VERSION ""

NS_ :

BS_:

BU_: BMS FRONT_SENSOR IMU INV LOGGER REAR_SENSOR VCU VCU_HP

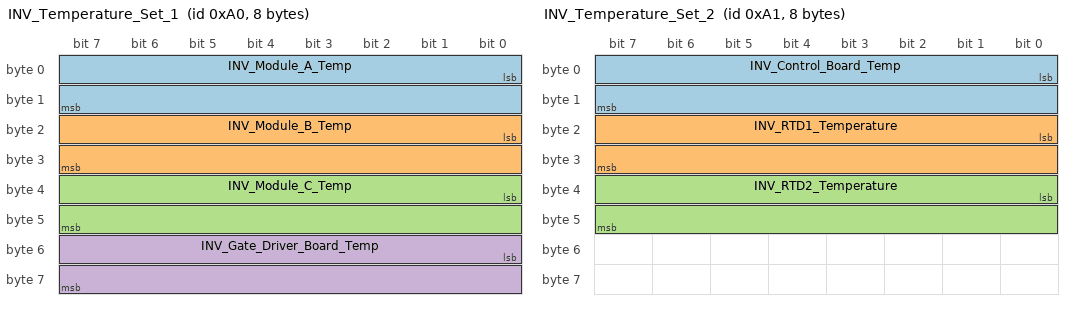
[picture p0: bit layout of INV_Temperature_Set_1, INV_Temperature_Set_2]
BO_ 160 INV_Temperature_Set_1: 8 INV
	SG_ INV_Module_A_Temp : 0|16@1- (0.1,0) [-3276.8|3276.7] "temperature:C" LOGGER
	SG_ INV_Module_B_Temp : 16|16@1- (0.1,0) [-3276.8|3276.7] "temperature:C" LOGGER
	SG_ INV_Module_C_Temp : 32|16@1- (0.1,0) [-3276.8|3276.7] "temperature:C" LOGGER
	SG_ INV_Gate_Driver_Board_Temp : 48|16@1- (0.1,0) [-3276.8|3276.7] "temperature:C" LOGGER

BO_ 161 INV_Temperature_Set_2: 8 INV
	SG_ INV_Control_Board_Temp : 0|16@1- (0.1,0) [-3276.8|3276.7] "temperature:C" LOGGER
	SG_ INV_RTD1_Temperature : 16|16@1- (0.1,0) [-3276.8|3276.7] "temperature:C" LOGGER
	SG_ INV_RTD2_Temperature : 32|16@1- (0.1,0) [-3276.8|3276.7] "temperature:C" LOGGER

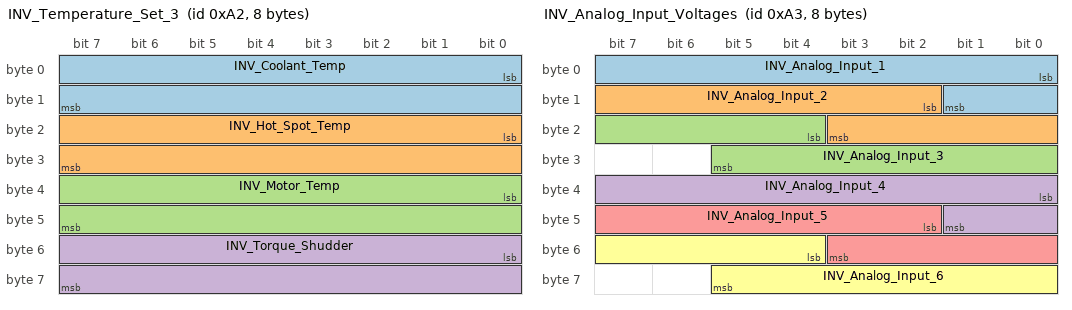
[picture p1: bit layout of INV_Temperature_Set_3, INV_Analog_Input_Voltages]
BO_ 162 INV_Temperature_Set_3: 8 INV
	SG_ INV_Coolant_Temp : 0|16@1- (0.1,0) [-3276.8|3276.7] "temperature:C" LOGGER
	SG_ INV_Hot_Spot_Temp : 16|16@1- (0.1,0) [-3276.8|3276.7] "temperature:C" LOGGER
	SG_ INV_Motor_Temp : 32|16@1- (0.1,0) [-3276.8|3276.7] "temperature:C" LOGGER
	SG_ INV_Torque_Shudder : 48|16@1- (0.1,0) [-3276.8|3276.7] "torque:N.m" LOGGER

BO_ 163 INV_Analog_Input_Voltages: 8 INV
	SG_ INV_Analog_Input_1 : 0|10@1+ (0.01,0) [0|10.23] "voltage:V" Vector__XXX
	SG_ INV_Analog_Input_2 : 10|10@1+ (0.01,0) [0|10.23] "voltage:V" Vector__XXX
	SG_ INV_Analog_Input_3 : 20|10@1+ (0.01,0) [0|10.23] "voltage:V" Vector__XXX
	SG_ INV_Analog_Input_4 : 32|10@1+ (0.01,0) [0|10.23] "voltage:V" Vector__XXX
	SG_ INV_Analog_Input_5 : 42|10@1+ (0.01,0) [0|10.23] "voltage:V" Vector__XXX
	SG_ INV_Analog_Input_6 : 52|10@1+ (0.01,0) [0|10.23] "voltage:V" Vector__XXX

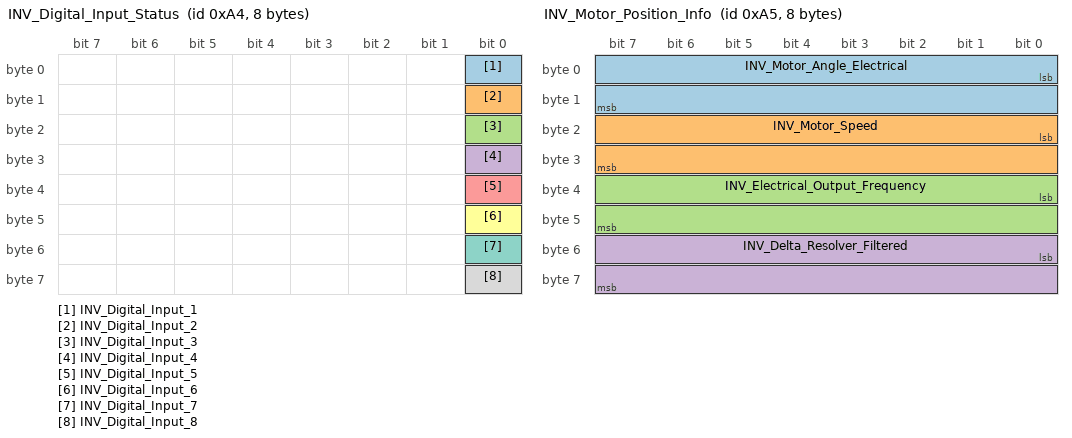
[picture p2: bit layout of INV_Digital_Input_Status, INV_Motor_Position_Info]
BO_ 164 INV_Digital_Input_Status: 8 INV
	SG_ INV_Digital_Input_1 : 0|1@1+ (1,0) [0|1] "" Vector__XXX
	SG_ INV_Digital_Input_2 : 8|1@1+ (1,0) [0|1] "" Vector__XXX
	SG_ INV_Digital_Input_3 : 16|1@1+ (1,0) [0|1] "" Vector__XXX
	SG_ INV_Digital_Input_4 : 24|1@1+ (1,0) [0|1] "" Vector__XXX
	SG_ INV_Digital_Input_5 : 32|1@1+ (1,0) [0|1] "" Vector__XXX
	SG_ INV_Digital_Input_6 : 40|1@1+ (1,0) [0|1] "" Vector__XXX
	SG_ INV_Digital_Input_7 : 48|1@1+ (1,0) [0|1] "" Vector__XXX
	SG_ INV_Digital_Input_8 : 56|1@1+ (1,0) [0|1] "" Vector__XXX

BO_ 165 INV_Motor_Position_Info: 8 INV
	SG_ INV_Motor_Angle_Electrical : 0|16@1+ (0.1,0) [0|6553.5] "angle:deg" LOGGER
	SG_ INV_Motor_Speed : 16|16@1- (1,0) [-32768|32767] "angular_speed:rpm" LOGGER
	SG_ INV_Electrical_Output_Frequency : 32|16@1- (0.1,0) [-3276.8|3276.7] "frequency:Hz" LOGGER
	SG_ INV_Delta_Resolver_Filtered : 48|16@1- (0.1,0) [-3276.8|3276.7] "angle:deg" LOGGER

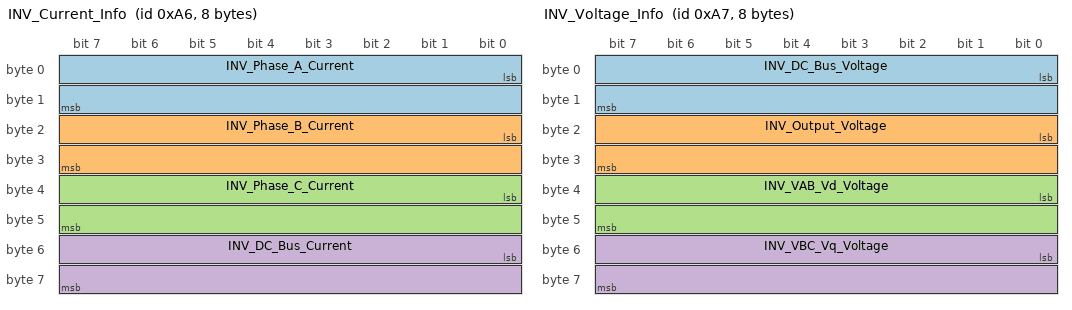
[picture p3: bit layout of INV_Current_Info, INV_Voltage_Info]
BO_ 166 INV_Current_Info: 8 INV
	SG_ INV_Phase_A_Current : 0|16@1- (0.1,0) [-3276.8|3276.7] "current:A" LOGGER
	SG_ INV_Phase_B_Current : 16|16@1- (0.1,0) [-3276.8|3276.7] "current:A" LOGGER
	SG_ INV_Phase_C_Current : 32|16@1- (0.1,0) [-3276.8|3276.7] "current:A" LOGGER
	SG_ INV_DC_Bus_Current : 48|16@1- (0.1,0) [-3276.8|3276.7] "current:A" LOGGER

BO_ 167 INV_Voltage_Info: 8 INV
	SG_ INV_DC_Bus_Voltage : 0|16@1- (0.1,0) [-3276.8|3276.7] "voltage:V" LOGGER
	SG_ INV_Output_Voltage : 16|16@1- (0.1,0) [-3276.8|3276.7] "voltage:V" LOGGER
	SG_ INV_VAB_Vd_Voltage : 32|16@1- (0.1,0) [-3276.8|3276.7] "voltage:V" LOGGER
	SG_ INV_VBC_Vq_Voltage : 48|16@1- (0.1,0) [-3276.8|3276.7] "voltage:V" LOGGER

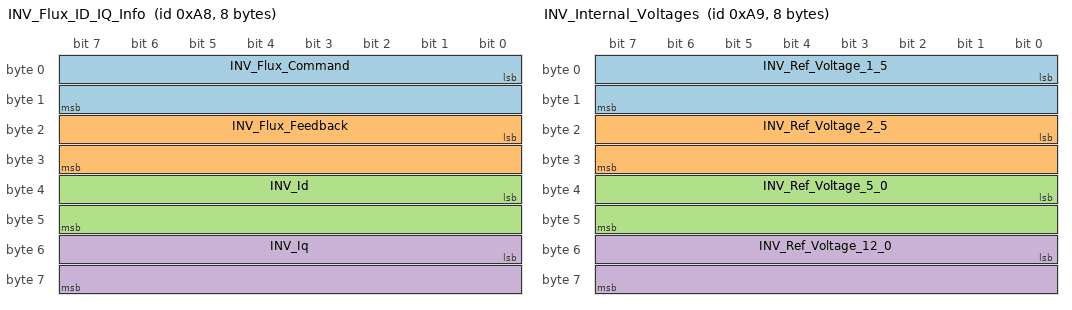
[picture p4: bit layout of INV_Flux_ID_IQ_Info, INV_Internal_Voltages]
BO_ 168 INV_Flux_ID_IQ_Info: 8 INV
	SG_ INV_Flux_Command : 0|16@1- (0.001,0) [-32.768|32.767] "flux:Wb" Vector__XXX
	SG_ INV_Flux_Feedback : 16|16@1- (0.001,0) [-32.768|32.767] "flux:Wb" Vector__XXX
	SG_ INV_Id : 32|16@1- (0.1,0) [-3276.8|3276.7] "current:A" Vector__XXX
	SG_ INV_Iq : 48|16@1- (0.1,0) [-3276.8|3276.7] "current:A" Vector__XXX

BO_ 169 INV_Internal_Voltages: 8 INV
	SG_ INV_Ref_Voltage_1_5 : 0|16@1- (0.01,0) [-327.68|327.67] "voltage:V" Vector__XXX
	SG_ INV_Ref_Voltage_2_5 : 16|16@1- (0.01,0) [-327.68|327.67] "voltage:V" Vector__XXX
	SG_ INV_Ref_Voltage_5_0 : 32|16@1- (0.01,0) [-327.68|327.67] "voltage:V" Vector__XXX
	SG_ INV_Ref_Voltage_12_0 : 48|16@1- (0.01,0) [-327.68|327.67] "voltage:V" Vector__XXX

BO_ 170 INV_Internal_States: 8 INV
	SG_ INV_VSM_State : 0|8@1+ (1,0) [0|15] "" LOGGER
	SG_ INV_PWM_Frequency : 8|8@1+ (1,0) [0|255] "" LOGGER
	SG_ INV_Inverter_State : 16|8@1+ (1,0) [0|255] "" LOGGER
	SG_ INV_Relay_1_Status : 24|1@1+ (1,0) [0|1] "" LOGGER
	SG_ INV_Relay_2_Status : 25|1@1+ (1,0) [0|1] "" LOGGER
	SG_ INV_Relay_3_Status : 26|1@1+ (1,0) [0|1] "" LOGGER
	SG_ INV_Relay_4_Status : 27|1@1+ (1,0) [0|1] "" LOGGER
	SG_ INV_Relay_5_Status : 28|1@1+ (1,0) [0|1] "" LOGGER
	SG_ INV_Relay_6_Status : 29|1@1+ (1,0) [0|1] "" LOGGER
	SG_ INV_Inverter_Run_Mode : 32|1@1+ (1,0) [0|1] "" LOGGER
	SG_ INV_Inverter_Discharge_State : 37|3@1+ (1,0) [0|7] "" LOGGER
	SG_ INV_Inverter_Command_Mode : 40|1@1+ (1,0) [0|1] "" LOGGER
	SG_ INV_Rolling_Counter : 44|4@1+ (1,0) [0|15] "" LOGGER
	SG_ INV_Inverter_Enable_State : 48|1@1+ (1,0) [0|1] "" LOGGER
	SG_ INV_Inverter_Enable_Lockout : 55|1@1+ (1,0) [0|1] "" LOGGER
	SG_ INV_Direction_Command : 56|1@1+ (1,0) [0|1] "" LOGGER
	SG_ INV_BMS_Active : 57|1@1+ (1,0) [0|1] "" LOGGER
	SG_ INV_BMS_Torque_Limiting : 58|1@1+ (1,0) [0|0] "" LOGGER
	SG_ INV_Limit_Max_Speed : 59|1@1+ (1,0) [0|1] "" LOGGER
	SG_ INV_Limit_Hot_Spot : 60|1@1+ (1,0) [0|1] "" LOGGER
	SG_ INV_Low_Speed_Limiting : 61|1@1+ (1,0) [0|1] "" LOGGER
	SG_ INV_Limit_Coolant_Derating : 62|1@1+ (1,0) [0|1] "" LOGGER

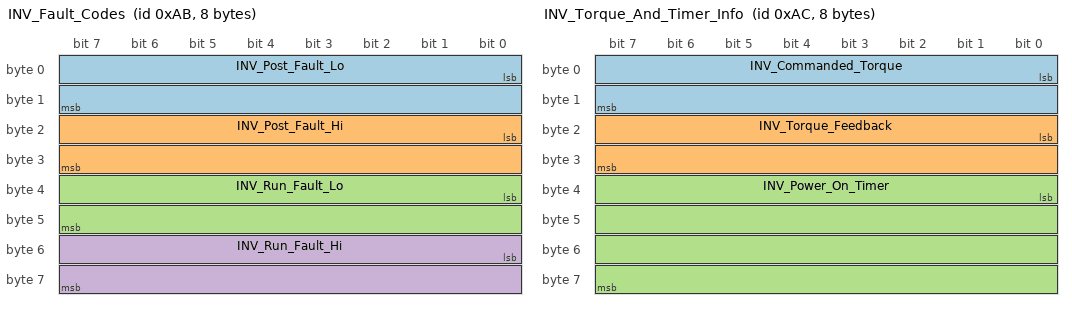
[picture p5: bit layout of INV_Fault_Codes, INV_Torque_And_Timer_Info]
BO_ 171 INV_Fault_Codes: 8 INV
	SG_ INV_Post_Fault_Lo : 0|16@1+ (1,0) [0|65535] "" LOGGER VCU
	SG_ INV_Post_Fault_Hi : 16|16@1+ (1,0) [0|65535] "" LOGGER VCU
	SG_ INV_Run_Fault_Lo : 32|16@1+ (1,0) [0|65535] "" LOGGER VCU
	SG_ INV_Run_Fault_Hi : 48|16@1+ (1,0) [0|65535] "" LOGGER VCU

BO_ 172 INV_Torque_And_Timer_Info: 8 INV
	SG_ INV_Commanded_Torque : 0|16@1- (0.1,0) [-3276.8|3276.7] "torque:N.m" Vector__XXX
	SG_ INV_Torque_Feedback : 16|16@1- (0.1,0) [-3276.8|3276.7] "torque:N.m" Vector__XXX
	SG_ INV_Power_On_Timer : 32|32@1+ (0.003,0) [0|12884800] "time:second" Vector__XXX

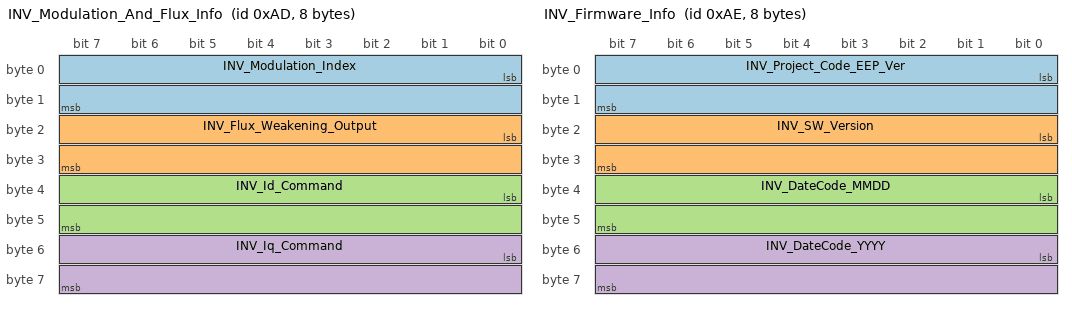
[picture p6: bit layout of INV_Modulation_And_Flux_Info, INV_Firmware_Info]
BO_ 173 INV_Modulation_And_Flux_Info: 8 INV
	SG_ INV_Modulation_Index : 0|16@1- (0.0001,0) [-3.2768|3.2767] "" Vector__XXX
	SG_ INV_Flux_Weakening_Output : 16|16@1- (0.1,0) [-3276.8|3276.7] "current:A" Vector__XXX
	SG_ INV_Id_Command : 32|16@1- (0.1,0) [-3276.8|3276.7] "current:A" Vector__XXX
	SG_ INV_Iq_Command : 48|16@1- (0.1,0) [-3276.8|3276.7] "current:A" Vector__XXX

BO_ 174 INV_Firmware_Info: 8 INV
	SG_ INV_Project_Code_EEP_Ver : 0|16@1+ (1,0) [0|65535] "" Vector__XXX
	SG_ INV_SW_Version : 16|16@1+ (1,0) [0|65535] "" Vector__XXX
	SG_ INV_DateCode_MMDD : 32|16@1+ (1,0) [0|65535] "" Vector__XXX
	SG_ INV_DateCode_YYYY : 48|16@1+ (1,0) [0|65535] "" Vector__XXX

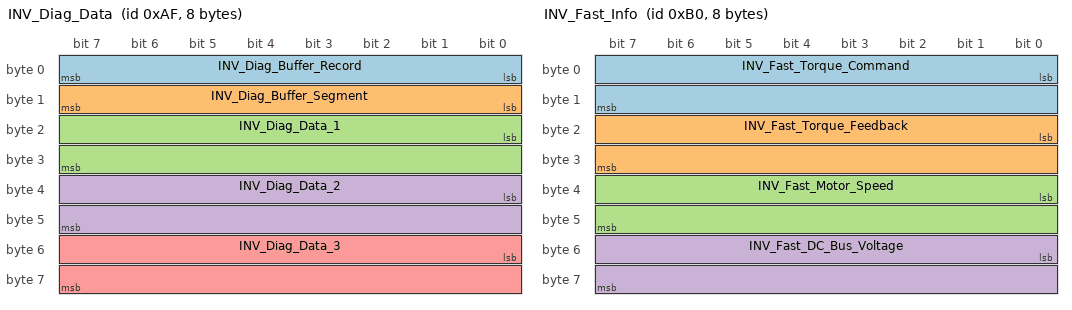
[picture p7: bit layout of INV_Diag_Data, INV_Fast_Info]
BO_ 175 INV_Diag_Data: 8 INV
	SG_ INV_Diag_Buffer_Record : 0|8@1+ (1,0) [0|255] "" Vector__XXX
	SG_ INV_Diag_Buffer_Segment : 8|8@1+ (1,0) [0|5] "" Vector__XXX
	SG_ INV_Diag_Data_1 : 16|16@1- (1,0) [-32768|32767] "" Vector__XXX
	SG_ INV_Diag_Data_2 : 32|16@1- (1,0) [-32768|32767] "" Vector__XXX
	SG_ INV_Diag_Data_3 : 48|16@1- (1,0) [-32768|32767] "" Vector__XXX

BO_ 176 INV_Fast_Info: 8 INV
	SG_ INV_Fast_Torque_Command : 0|16@1- (0.1,0) [-3276.8|32767.7] "torque:N.m" LOGGER, VCU_HP
	SG_ INV_Fast_Torque_Feedback : 16|16@1- (0.1,0) [-3276.8|3276.7] "torque:N.m" LOGGER, VCU_HP
	SG_ INV_Fast_Motor_Speed : 32|16@1- (1,0) [-32768|32767] "angular_speed:rpm" LOGGER, VCU_HP
	SG_ INV_Fast_DC_Bus_Voltage : 48|16@1- (0.1,0) [-3276.8|3276.7] "voltage:V" LOGGER, VCU_HP

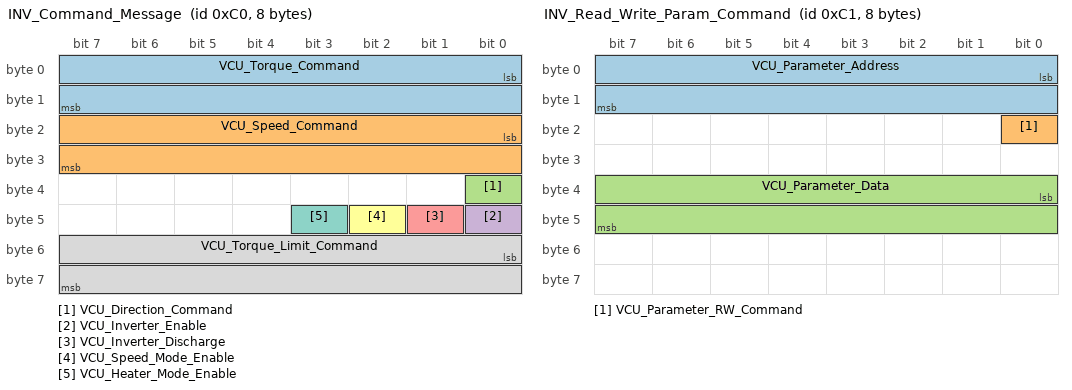
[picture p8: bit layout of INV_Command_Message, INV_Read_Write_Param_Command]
BO_ 192 INV_Command_Message: 8 VCU
	SG_ VCU_Torque_Command : 0|16@1- (0.1,0) [-3276.8|3276.7] "torque:N.m" INV, LOGGER
	SG_ VCU_Speed_Command : 16|16@1- (1,0) [-32768|32767] "angular_speed:rpm" INV, LOGGER
	SG_ VCU_Direction_Command : 32|1@1+ (1,0) [0|1] "" INV, LOGGER
	SG_ VCU_Inverter_Enable : 40|1@1+ (1,0) [0|1] "" INV, LOGGER
	SG_ VCU_Inverter_Discharge : 41|1@1+ (1,0) [0|1] "" INV, LOGGER
	SG_ VCU_Speed_Mode_Enable : 42|1@1+ (1,0) [0|1] "" INV, LOGGER
	SG_ VCU_Heater_Mode_Enable : 43|1@1+ (1,0) [0|0] "" INV, LOGGER
	SG_ VCU_Torque_Limit_Command : 48|16@1- (0.1,0) [-3276.8|3276.7] "torque:N.m" INV, LOGGER

BO_ 193 INV_Read_Write_Param_Command: 8 Vector__XXX
	SG_ VCU_Parameter_Address : 0|16@1+ (1,0) [0|65535] "" INV
	SG_ VCU_Parameter_RW_Command : 16|1@1+ (1,0) [0|1] "" INV
	SG_ VCU_Parameter_Data : 32|16@1- (1,0) [-32768|32767] "" INV

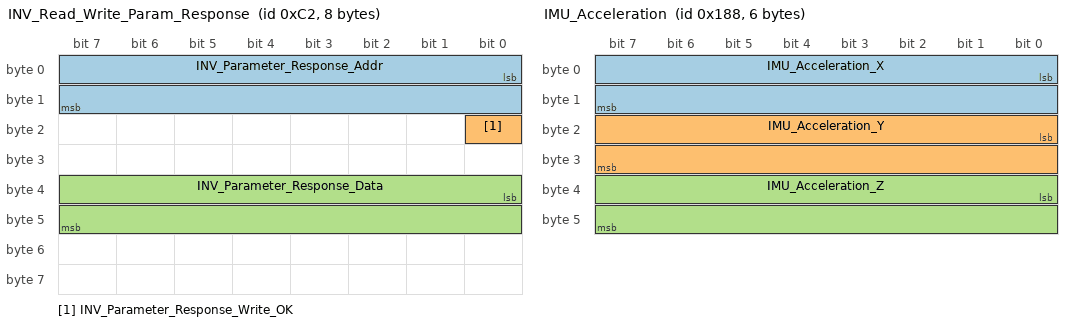
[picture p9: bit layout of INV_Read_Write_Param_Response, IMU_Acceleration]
BO_ 194 INV_Read_Write_Param_Response: 8 INV
	SG_ INV_Parameter_Response_Addr : 0|16@1+ (1,0) [0|65535] "" Vector__XXX
	SG_ INV_Parameter_Response_Write_OK : 16|1@1+ (1,0) [0|1] "" Vector__XXX
	SG_ INV_Parameter_Response_Data : 32|16@1- (1,0) [-32768|32767] "" Vector__XXX

BO_ 392 IMU_Acceleration: 6 IMU
	SG_ IMU_Acceleration_X : 0|16@1- (0.001,0) [-8|8] "acceleration:G" LOGGER
	SG_ IMU_Acceleration_Y : 16|16@1- (0.001,0) [-8|8] "acceleration:G" LOGGER
	SG_ IMU_Acceleration_Z : 32|16@1- (0.001,0) [-8|8] "acceleration:G" LOGGER

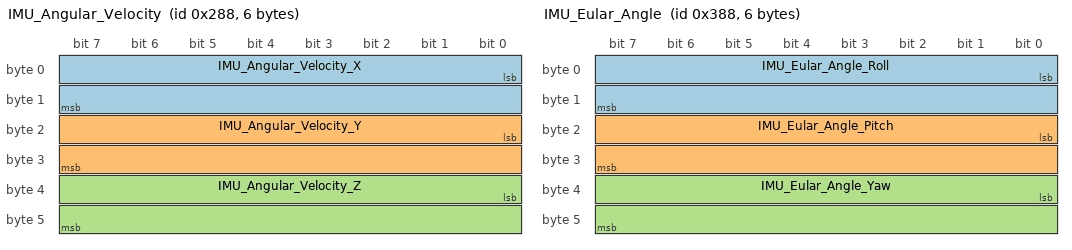
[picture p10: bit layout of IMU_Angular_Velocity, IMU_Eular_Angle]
BO_ 648 IMU_Angular_Velocity: 6 IMU
	SG_ IMU_Angular_Velocity_X : 0|16@1- (0.1,0) [-2000|2000] "angular_velocity:deg/s" LOGGER
	SG_ IMU_Angular_Velocity_Y : 16|16@1- (0.1,0) [-2000|2000] "angular_velocity:deg/s" LOGGER
	SG_ IMU_Angular_Velocity_Z : 32|16@1- (0.1,0) [-2000|2000] "angular_velocity:deg/s" LOGGER

BO_ 904 IMU_Eular_Angle: 6 IMU
	SG_ IMU_Eular_Angle_Roll : 0|16@1- (0.01,0) [-180|180] "angle:deg" Vector__XXX
	SG_ IMU_Eular_Angle_Pitch : 16|16@1- (0.01,0) [-90|90] "angle:deg" Vector__XXX
	SG_ IMU_Eular_Angle_Yaw : 32|16@1- (0.01,0) [-180|180] "angle:deg" Vector__XXX

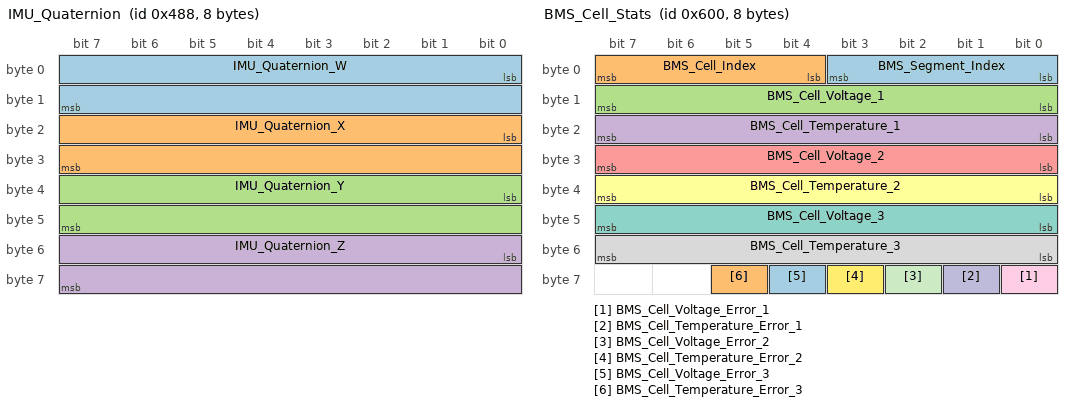
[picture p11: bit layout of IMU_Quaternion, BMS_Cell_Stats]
BO_ 1160 IMU_Quaternion: 8 IMU
	SG_ IMU_Quaternion_W : 0|16@1- (0.0001,0) [-1|1] "" LOGGER
	SG_ IMU_Quaternion_X : 16|16@1- (0.0001,0) [-1|1] "" LOGGER
	SG_ IMU_Quaternion_Y : 32|16@1- (0.0001,0) [-1|1] "" LOGGER
	SG_ IMU_Quaternion_Z : 48|16@1- (0.0001,0) [-1|1] "" LOGGER

BO_ 1536 BMS_Cell_Stats: 8 BMS
	SG_ BMS_Segment_Index : 0|4@1+ (1,0) [0|15] "" LOGGER
	SG_ BMS_Cell_Index : 4|4@1+ (1,0) [0|3] "" LOGGER
	SG_ BMS_Cell_Voltage_1 : 8|8@1+ (0.01,2) [2|4.55] "voltage:V" LOGGER
	SG_ BMS_Cell_Temperature_1 : 16|8@1+ (0.3125,-20) [0|0] "temperature:C" LOGGER
	SG_ BMS_Cell_Voltage_2 : 24|8@1+ (0.01,2) [2|4.55] "voltage:V" LOGGER
	SG_ BMS_Cell_Temperature_2 : 32|8@1+ (0.3125,-20) [0|0] "temperature:C" LOGGER
	SG_ BMS_Cell_Voltage_3 : 40|8@1+ (0.01,2) [2|4.55] "voltage:V" LOGGER
	SG_ BMS_Cell_Temperature_3 : 48|8@1+ (0.3125,-20) [0|0] "temperature:C" LOGGER
	SG_ BMS_Cell_Voltage_Error_1 : 56|1@1+ (1,0) [0|0] "" LOGGER
	SG_ BMS_Cell_Temperature_Error_1 : 57|1@1+ (1,0) [0|0] "" LOGGER
	SG_ BMS_Cell_Voltage_Error_2 : 58|1@1+ (1,0) [0|0] "" LOGGER
	SG_ BMS_Cell_Temperature_Error_2 : 59|1@1+ (1,0) [0|0] "" LOGGER
	SG_ BMS_Cell_Voltage_Error_3 : 60|1@1+ (1,0) [0|0] "" LOGGER
	SG_ BMS_Cell_Temperature_Error_3 : 61|1@1+ (1,0) [0|0] "" LOGGER

BO_ 1537 BMS_Status: 1 BMS
	SG_ BMS_Error_Code : 0|4@1+ (1,0) [0|0] "" VCU, LOGGER

BO_ 1672 IMU_Pressure: 4 IMU
	SG_ IMU_Pressure : 0|32@1+ (1,0) [0|0] "pressure:Pa" LOGGER

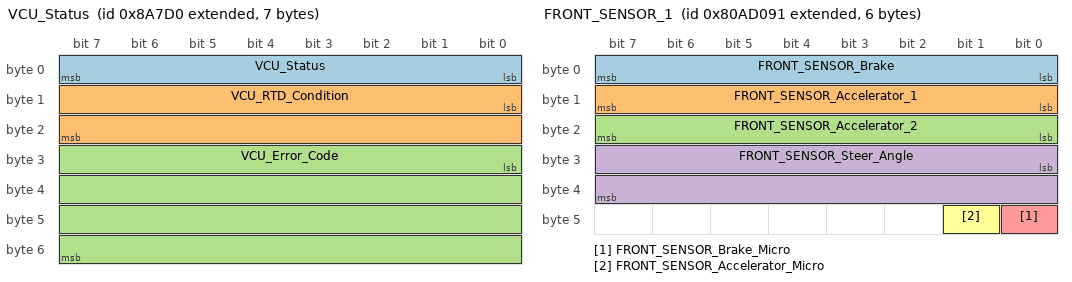
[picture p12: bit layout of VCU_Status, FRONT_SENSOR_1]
BO_ 2148050896 VCU_Status: 7 VCU
	SG_ VCU_Status : 0|8@1+ (1,0) [0|0] "" LOGGER
	SG_ VCU_RTD_Condition : 8|16@1+ (1,0) [0|0] "" LOGGER
	SG_ VCU_Error_Code : 24|32@1+ (1,0) [0|0] "" LOGGER

BO_ 2148050897 REAR_SENSOR_Status: 5 REAR_SENSOR
	SG_ REAR_SENSOR_Status : 0|8@1+ (1,0) [0|0] "" LOGGER
	SG_ REAR_SENSOR_Error_Code : 8|32@1+ (1,0) [0|0] "" VCU LOGGER

BO_ 2282410129 FRONT_SENSOR_1: 6 FRONT_SENSOR
	SG_ FRONT_SENSOR_Brake : 0|8@1+ (0.004,0) [0|1] "" LOGGER
	SG_ FRONT_SENSOR_Accelerator_1 : 8|8@1+ (0.004,0) [0|1] "" LOGGER
	SG_ FRONT_SENSOR_Accelerator_2 : 16|8@1+ (0.004,0) [0|1] "" LOGGER
	SG_ FRONT_SENSOR_Steer_Angle : 24|16@1- (1,0) [0|0] "angle:deg" LOGGER
	SG_ FRONT_SENSOR_Brake_Micro : 40|1@1+ (1,0) [0|1] "" REAR_SENSOR LOGGER
	SG_ FRONT_SENSOR_Accelerator_Micro : 41|1@1+ (1,0) [0|1] "" LOGGER

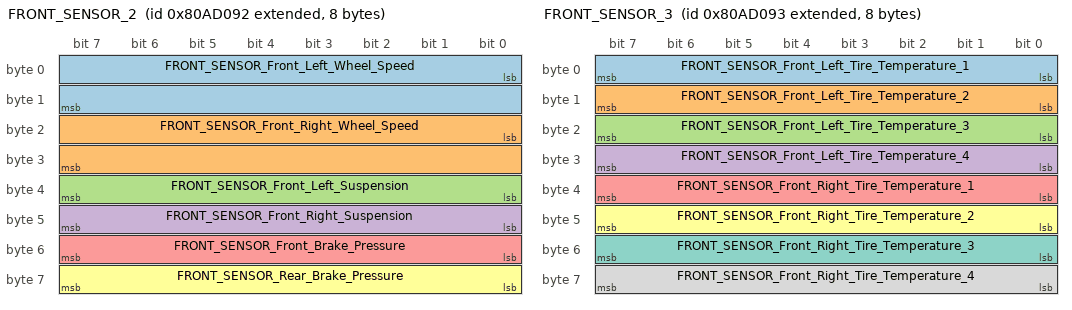
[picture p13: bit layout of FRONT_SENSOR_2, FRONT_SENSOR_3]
BO_ 2282410130 FRONT_SENSOR_2: 8 FRONT_SENSOR
	SG_ FRONT_SENSOR_Front_Left_Wheel_Speed : 0|16@1- (0.1,0) [0|0] "angular_velocity:rpm" LOGGER
	SG_ FRONT_SENSOR_Front_Right_Wheel_Speed : 16|16@1- (0.1,0) [0|0] "angular_velocity:rpm" LOGGER
	SG_ FRONT_SENSOR_Front_Left_Suspension : 32|8@1+ (0.1,30) [0|0] "length:mm" LOGGER
	SG_ FRONT_SENSOR_Front_Right_Suspension : 40|8@1+ (0.1,30) [0|0]"length:mm" LOGGER
	SG_ FRONT_SENSOR_Front_Brake_Pressure : 48|8@1+ (0.3,0) [0|1] "pressure:bar" LOGGER
	SG_ FRONT_SENSOR_Rear_Brake_Pressure : 56|8@1+ (0.3,0) [0|1] "pressure:bar" LOGGER

BO_ 2282410131 FRONT_SENSOR_3: 8 FRONT_SENSOR
	SG_ FRONT_SENSOR_Front_Left_Tire_Temperature_1 : 0|8@1+ (0.2,30) [0|0] "temperature:C" LOGGER
	SG_ FRONT_SENSOR_Front_Left_Tire_Temperature_2 : 8|8@1+ (0.2,30) [0|0] "temperature:C" LOGGER
	SG_ FRONT_SENSOR_Front_Left_Tire_Temperature_3 : 16|8@1+ (0.2,30) [0|0] "temperature:C" LOGGER
	SG_ FRONT_SENSOR_Front_Left_Tire_Temperature_4 : 24|8@1+ (0.2,30) [0|0] "temperature:C" LOGGER
	SG_ FRONT_SENSOR_Front_Right_Tire_Temperature_1 : 32|8@1+ (0.2,30) [0|0] "temperature:C" LOGGER
	SG_ FRONT_SENSOR_Front_Right_Tire_Temperature_2 : 40|8@1+ (0.2,30) [0|0] "temperature:C" LOGGER
	SG_ FRONT_SENSOR_Front_Right_Tire_Temperature_3 : 48|8@1+ (0.2,30) [0|0] "temperature:C" LOGGER
	SG_ FRONT_SENSOR_Front_Right_Tire_Temperature_4 : 56|8@1+ (0.2,30) [0|0] "temperature:C" LOGGER

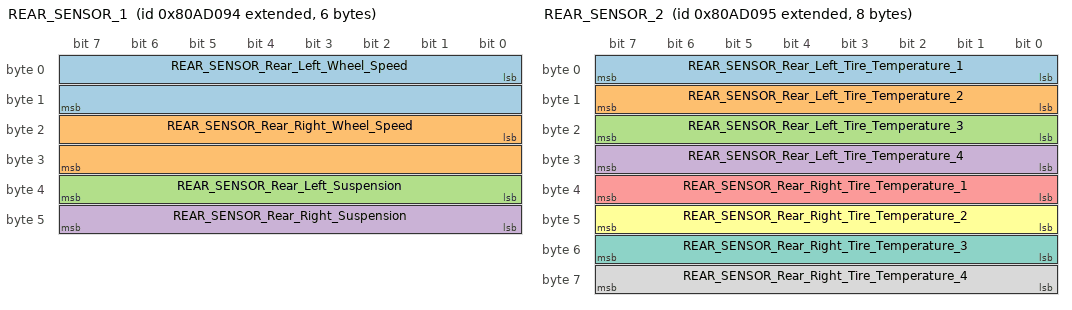
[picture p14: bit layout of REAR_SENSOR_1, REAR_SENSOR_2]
BO_ 2282410132 REAR_SENSOR_1: 6 REAR_SENSOR
	SG_ REAR_SENSOR_Rear_Left_Wheel_Speed : 0|16@1- (0.1,0) [0|0] "angular_velocity:rpm" LOGGER
	SG_ REAR_SENSOR_Rear_Right_Wheel_Speed : 16|16@1- (0.1,0) [0|0] "angular_velocity:rpm" LOGGER
	SG_ REAR_SENSOR_Rear_Left_Suspension : 32|8@1+ (0.1,30) [0|0] "length:mm" LOGGER
	SG_ REAR_SENSOR_Rear_Right_Suspension : 40|8@1+ (0.1,30) [0|0]"length:mm" LOGGER

BO_ 2282410133 REAR_SENSOR_2: 8 REAR_SENSOR
	SG_ REAR_SENSOR_Rear_Left_Tire_Temperature_1 : 0|8@1+ (0.2,30) [0|0] "temperature:C" LOGGER
	SG_ REAR_SENSOR_Rear_Left_Tire_Temperature_2 : 8|8@1+ (0.2,30) [0|0] "temperature:C" LOGGER
	SG_ REAR_SENSOR_Rear_Left_Tire_Temperature_3 : 16|8@1+ (0.2,30) [0|0] "temperature:C" LOGGER
	SG_ REAR_SENSOR_Rear_Left_Tire_Temperature_4 : 24|8@1+ (0.2,30) [0|0] "temperature:C" LOGGER
	SG_ REAR_SENSOR_Rear_Right_Tire_Temperature_1 : 32|8@1+ (0.2,30) [0|0] "temperature:C" LOGGER
	SG_ REAR_SENSOR_Rear_Right_Tire_Temperature_2 : 40|8@1+ (0.2,30) [0|0] "temperature:C" LOGGER
	SG_ REAR_SENSOR_Rear_Right_Tire_Temperature_3 : 48|8@1+ (0.2,30) [0|0] "temperature:C" LOGGER
	SG_ REAR_SENSOR_Rear_Right_Tire_Temperature_4 : 56|8@1+ (0.2,30) [0|0] "temperature:C" LOGGER

CM_ SG_ 160 INV_Module_A_Temp "IGBT Module A Temperature";
CM_ SG_ 160 INV_Module_B_Temp "IGBT Module B Temperature";
CM_ SG_ 160 INV_Module_C_Temp "IGBT Module C Temperature";
CM_ SG_ 160 INV_Gate_Driver_Board_Temp "Gate Driver Board Temperature";

CM_ SG_ 161 INV_Control_Board_Temp "Control Board Temperature";
CM_ SG_ 161 INV_RTD1_Temperature "RTD input 1 (PT1000) Temperature";
CM_ SG_ 161 INV_RTD2_Temperature "RTD input 2 (PT1000) Temperature";

CM_ SG_ 162 INV_Coolant_Temp "Estimated Coolant Temperature";
CM_ SG_ 162 INV_Hot_Spot_Temp "Estimated inverter hot spot temperature";
CM_ SG_ 162 INV_Motor_Temp "Motor Temperature Sensor";
CM_ SG_ 162 INV_Torque_Shudder "Shudder compensation value of torque";

CM_ SG_ 163 INV_Analog_Input_1 "Voltage on Analog Input #1";
CM_ SG_ 163 INV_Analog_Input_2 "Voltage on Analog Input #2";
CM_ SG_ 163 INV_Analog_Input_3 "Voltage on Analog Input #3";
CM_ SG_ 163 INV_Analog_Input_4 "Voltage on Analog Input #4";
CM_ SG_ 163 INV_Analog_Input_5 "Voltage on Analog Input #5";
CM_ SG_ 163 INV_Analog_Input_6 "Voltage on Analog Input #6";

CM_ SG_ 164 INV_Digital_Input_1 "Status of Digital Input #1";
CM_ SG_ 164 INV_Digital_Input_2 "Status of Digital Input #2";
CM_ SG_ 164 INV_Digital_Input_3 "Status of Digital Input #3";
CM_ SG_ 164 INV_Digital_Input_4 "Status of Digital Input #4";
CM_ SG_ 164 INV_Digital_Input_5 "Status of Digital Input #5";
CM_ SG_ 164 INV_Digital_Input_6 "Status of Digital Input #6";
CM_ SG_ 164 INV_Digital_Input_7 "Status of Digital Input #7";
CM_ SG_ 164 INV_Digital_Input_8 "Status of Digital Input #8";

CM_ SG_ 165 INV_Motor_Angle_Electrical "The Electrical Angle of the motor as read by the encoder or resolver";
CM_ SG_ 165 INV_Motor_Speed "The measured speed of the motor";
CM_ SG_ 165 INV_Electrical_Output_Frequency "The actual electrical frequency of the inverter";
CM_ SG_ 165 INV_Delta_Resolver_Filtered "Used in calibration of resolver angle adjustment.";

CM_ SG_ 166 INV_Phase_A_Current "The measured value of Phase A current";
CM_ SG_ 166 INV_Phase_B_Current "The measured value of Phase B current";
CM_ SG_ 166 INV_Phase_C_Current "The measured value of Phase C current";
CM_ SG_ 166 INV_DC_Bus_Current "The Calculated DC Bus Current";

CM_ SG_ 167 INV_DC_Bus_Voltage "The actual measured value of the DC bus voltage";
CM_ SG_ 167 INV_Output_Voltage "The calculated value of the output voltage, in peak line-neutral volts";
CM_ SG_ 167 INV_VAB_Vd_Voltage "Measured value of the voltage betwen phase A and Phase B";
CM_ SG_ 167 INV_VBC_Vq_Voltage "Measured value of the voltage between Phase B and Phase C";

CM_ SG_ 168 INV_Flux_Command "The commanded flux";
CM_ SG_ 168 INV_Flux_Feedback "The estimated flux";
CM_ SG_ 168 INV_Id "The measured Id current";
CM_ SG_ 168 INV_Iq "The measured Iq current";

CM_ SG_ 169 INV_Ref_Voltage_1_5 "Internal reference voltage";
CM_ SG_ 169 INV_Ref_Voltage_2_5 "Internal reference voltage";
CM_ SG_ 169 INV_Ref_Voltage_5_0 "Transducer voltage";
CM_ SG_ 169 INV_Ref_Voltage_12_0 "12V Input Voltage";

CM_ SG_ 170 INV_VSM_State "Different states for the vehicle state machine";
CM_ SG_ 170 INV_PWM_Frequency "The current active PWM frequency";
CM_ SG_ 170 INV_Inverter_State "Different states for the inverter state machine";
CM_ SG_ 170 INV_Relay_1_Status "0=OFF, 1=ON";
CM_ SG_ 170 INV_Relay_2_Status "0=OFF, 1=ON";
CM_ SG_ 170 INV_Relay_3_Status "0=OFF, 1=ON";
CM_ SG_ 170 INV_Relay_4_Status "0=OFF, 1=ON";
CM_ SG_ 170 INV_Relay_5_Status "0=OFF, 1=ON";
CM_ SG_ 170 INV_Relay_6_Status "0=OFF, 1=ON";
CM_ SG_ 170 INV_Inverter_Run_Mode "0=Torque Mode, 1=Speed Mode";
CM_ SG_ 170 INV_Inverter_Discharge_State "0 = Disabled, 1 = Enabled, 2 = Speed Check, 3 = Active, 4 = Complete";
CM_ SG_ 170 INV_Inverter_Command_Mode "0=CAN mode, 1=VSM mode";
CM_ SG_ 170 INV_Rolling_Counter "Rolling Counter value";
CM_ SG_ 170 INV_Inverter_Enable_State "0=Inverter Disabled, 1=Inverter Enabled";
CM_ SG_ 170 INV_Inverter_Enable_Lockout "0=Lockout Disabled, 1=Lockout Enabled";
CM_ SG_ 170 INV_Direction_Command "1 = Forward, 0 = 'Reverse' if inverter enabled  & 'Stopped' if inverter is disabled";
CM_ SG_ 170 INV_BMS_Active "0 = BMS Not Active, 1 = BMS Active";
CM_ SG_ 170 INV_BMS_Torque_Limiting "0 = Not Limiting, 1 = Limiting";
CM_ SG_ 170 INV_Limit_Max_Speed "Indicates that torque is being modified to limit the speed.";
CM_ SG_ 170 INV_Limit_Hot_Spot "Indicates that torque is being limited to limit the hot spot temp";
CM_ SG_ 170 INV_Low_Speed_Limiting "Indicates that motor current is being limited due to low motor electrical frequency.";
CM_ SG_ 170 INV_Limit_Coolant_Derating "0 = Not limiting, 1 = Limiting";

CM_ SG_ 171 INV_Post_Fault_Lo "Each bit represents a fault. Please refer to PM100 Users Manual for details.";
CM_ SG_ 171 INV_Post_Fault_Hi "Each bit represents a fault. Please refer to PM100 Users Manual for details.";
CM_ SG_ 171 INV_Run_Fault_Lo "Each bit represents a fault. Please refer to PM100 Users Manual for details.";
CM_ SG_ 171 INV_Run_Fault_Hi "Each bit represents a fault. Please refer to PM100 Users Manual for details.";

CM_ SG_ 172 INV_Commanded_Torque "The commanded Torque";
CM_ SG_ 172 INV_Torque_Feedback "Estimated motor torque feedback";
CM_ SG_ 172 INV_Power_On_Timer "Updated every 3 msec. This will roll over in approximately 150 days!";

CM_ SG_ 173 INV_Modulation_Index "This is the modulation index. The scale factor is x100. To get the actual modulation index divide the value by 100.";
CM_ SG_ 173 INV_Flux_Weakening_Output "This is the current output of the flux regulator.";
CM_ SG_ 173 INV_Id_Command "The commanded D-axis current";
CM_ SG_ 173 INV_Iq_Command "The commanded Q-axis current";

CM_ BO_ 176 "To enable fast message set CAN ACTIVE MSGS HI WORD to 0xFFFE.  Setting to default value of 0xFFFF will disable the fast message.";
CM_ SG_ 176 INV_Fast_Torque_Command "The commanded torque";
CM_ SG_ 176 INV_Fast_Torque_Feedback "The estimated torque";
CM_ SG_ 176 INV_Fast_Motor_Speed "Motor speed";
CM_ SG_ 176 INV_Fast_DC_Bus_Voltage "DC Bus Voltage";

CM_ BO_ 192 "The command message is used to transmit data to the controller. This message is sent from a user supplied external controller to the PMxxx controller.";
CM_ SG_ 192 VCU_Torque_Command "Torque command when in torque mode";
CM_ SG_ 192 VCU_Speed_Command "Speed command used when in speed mode";
CM_ SG_ 192 VCU_Direction_Command "0=Reverse, 1=Forward.  Forward is positive motor speed.";
CM_ SG_ 192 VCU_Inverter_Enable "0=Inverter OFF, 1 = Inverter ON";
CM_ SG_ 192 VCU_Inverter_Discharge "0=Discharge Disable,1=Discharge Enable";
CM_ SG_ 192 VCU_Speed_Mode_Enable "0 = No change to mode, 1 = change to speed mode from torque mode";
CM_ SG_ 192 VCU_Heater_Mode_Enable "0 = Use run table, 1 = Use heater table";
CM_ SG_ 192 VCU_Torque_Limit_Command "Torque Limit, set to 0 to keep default";

CM_ BO_ 193 "To write a parameter use message 0x0C1 with byte #2 set to 1 (write). To read a parameter use message 0x0C1 with byte #2 to set 0 (read). ";
CM_ SG_ 193 VCU_Parameter_Address "Address of parameter to be written or read.";
CM_ SG_ 193 VCU_Parameter_RW_Command "0=Read, 1=Write";
CM_ SG_ 193 VCU_Parameter_Data "Data to be written.  All data is 16 bits and is contained in bytes 4 and 5.";

CM_ BO_ 194 "To write a parameter use message 0x0C1 with byte #2 set to 1 (write). To read a parameter use message 0x0C1 with byte #2 to set 0 (read). ";
CM_ SG_ 194 INV_Parameter_Response_Addr "Address of parameter response message data.";
CM_ SG_ 194 INV_Parameter_Response_Write_OK "0=Write failure, 1=Success";
CM_ SG_ 194 INV_Parameter_Response_Data "Data from parameter message.  All data is 16 bits and is contained in bytes 4 and 5. Bytes 6 and 7 should be ignored.";

BA_DEF_ BO_  "GenMsgCycleTime" INT 0 100000;
BA_DEF_  "BusType" STRING ;
BA_DEF_DEF_  "GenMsgCycleTime" 0;
BA_DEF_DEF_  "BusType" "CAN";

BA_ "GenMsgCycleTime" BO_ 160 100;
BA_ "GenMsgCycleTime" BO_ 161 100;
BA_ "GenMsgCycleTime" BO_ 162 100;
BA_ "GenMsgCycleTime" BO_ 163 10;
BA_ "GenMsgCycleTime" BO_ 164 10;
BA_ "GenMsgCycleTime" BO_ 165 10;
BA_ "GenMsgCycleTime" BO_ 166 10;
BA_ "GenMsgCycleTime" BO_ 167 10;
BA_ "GenMsgCycleTime" BO_ 168 10;
BA_ "GenMsgCycleTime" BO_ 169 100;
BA_ "GenMsgCycleTime" BO_ 170 100;
BA_ "GenMsgCycleTime" BO_ 171 100;
BA_ "GenMsgCycleTime" BO_ 172 10;
BA_ "GenMsgCycleTime" BO_ 176 3;
BA_ "GenMsgCycleTime" BO_ 192 10;
BA_ "GenMsgCycleTime" BO_ 392 100;
BA_ "GenMsgCycleTime" BO_ 514 100;
BA_ "GenMsgCycleTime" BO_ 648 100;
BA_ "GenMsgCycleTime" BO_ 904 100;
BA_ "GenMsgCycleTime" BO_ 1160 100;
BA_ "GenMsgCycleTime" BO_ 1536 300;
BA_ "GenMsgCycleTime" BO_ 1537 300;
BA_ "GenMsgCycleTime" BO_ 1672 20;
BA_ "GenMsgCycleTime" BO_ 2148050896 100;
BA_ "GenMsgCycleTime" BO_ 2148050897 100;
BA_ "GenMsgCycleTime" BO_ 2282410129 100;
BA_ "GenMsgCycleTime" BO_ 2282410130 100;
BA_ "GenMsgCycleTime" BO_ 2282410131 100;
BA_ "GenMsgCycleTime" BO_ 2282410132 100;
BA_ "GenMsgCycleTime" BO_ 2282410133 100;

VAL_ 170 INV_VSM_State 0 "VSM Start State" 1 "Pre-Charge Init state" 2 "pre-charge active state" 3 "pre-charge complete state" 4 "VSM wait state" 5 "VSM ready state" 6 "Motor Running State" 7 "blink fault code state" 14 "Shutdown state for Key Switch Mode 1" 15 "Reset the inverter" ;
VAL_ 170 INV_Inverter_State 0 "Power up" 1 "Stop" 2 "Open Loop" 3 "Closed Loop" 4 "Internal State" 5 "Internal State" 6 "Internal State" 7 "Internal State" 8 "Idle Run" 9 "Idle Stop" 10 "Internal State" 11 "Intern State" 12 "Internal State" ;
VAL_ 192 VCU_Direction_Command 0 "CW" 1 "CCW" ;
VAL_ 192 VCU_Inverter_Enable 0 "Turn the inverter OFF" 1 "Turn the Inverter ON" ;
VAL_ 192 VCU_Inverter_Discharge 0 "Discharge Disable" 1 "Discharge Enable (if EEPROM parameter is set)" ;
